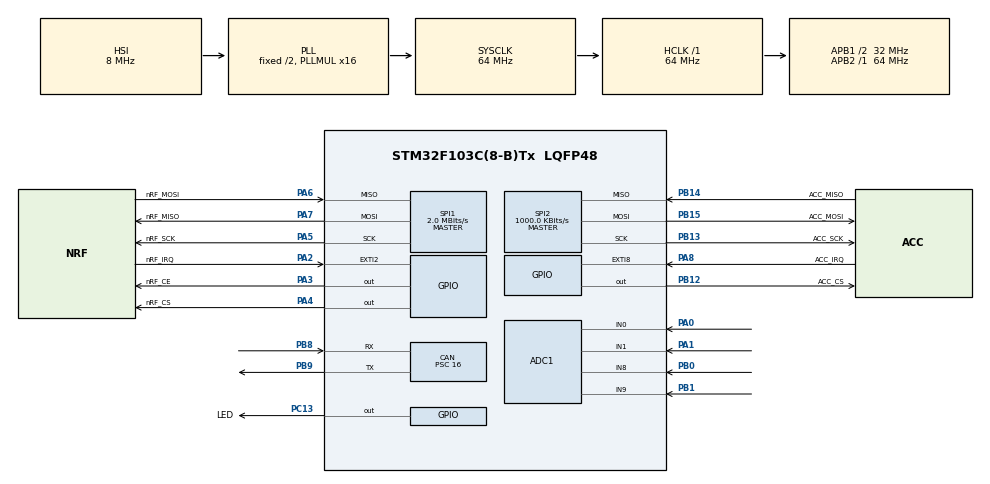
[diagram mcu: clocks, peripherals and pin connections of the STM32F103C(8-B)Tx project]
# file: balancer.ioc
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ADC1.Channel-0\#ChannelRegularConversion=ADC_CHANNEL_0
ADC1.Channel-1\#ChannelRegularConversion=ADC_CHANNEL_1
ADC1.Channel-2\#ChannelRegularConversion=ADC_CHANNEL_8
ADC1.Channel-3\#ChannelRegularConversion=ADC_CHANNEL_9
ADC1.ContinuousConvMode=DISABLE
ADC1.NbrOfConversion=4
ADC1.NbrOfConversionFlag=1
ADC1.Rank-0\#ChannelRegularConversion=1
ADC1.Rank-1\#ChannelRegularConversion=2
ADC1.Rank-2\#ChannelRegularConversion=3
ADC1.Rank-3\#ChannelRegularConversion=4
ADC1.SamplingTime-0\#ChannelRegularConversion=ADC_SAMPLETIME_1CYCLE_5
ADC1.SamplingTime-1\#ChannelRegularConversion=ADC_SAMPLETIME_1CYCLE_5
ADC1.SamplingTime-2\#ChannelRegularConversion=ADC_SAMPLETIME_1CYCLE_5
ADC1.SamplingTime-3\#ChannelRegularConversion=ADC_SAMPLETIME_1CYCLE_5
ADC1.master=1
CAN.BS1=CAN_BS1_2TQ
CAN.CalculateBaudRate=500000
CAN.CalculateTimeBit=2000
CAN.CalculateTimeQuantum=500.0
CAN.Mode=CAN_MODE_NORMAL
CAN.Prescaler=16
FREERTOS.Events01=myEvent01,Static,myEvent01ControlBlock
FREERTOS.Mutexes01=myMutex01,Static,myMutex01ControlBlock,Available
FREERTOS.Tasks01=defaultTask,24,128,StartDefaultTask,Default,NULL,Dynamic,NULL,NULL
FREERTOS.configUSE_NEWLIB_REENTRANT=1
FREERTOS.configUSE_TICKLESS_IDLE=1
Mcu.Family=STM32F1
Mcu.Name=STM32F103C(8-B)Tx
Mcu.Package=LQFP48
NVIC.CAN1_RX1_IRQn=true\:5\:0\:false\:false\:true\:true\:true\:true\:true
NVIC.EXTI2_IRQn=true\:8\:0\:true\:false\:true\:true\:true\:true\:true
NVIC.EXTI9_5_IRQn=true\:5\:0\:false\:false\:true\:true\:true\:true\:true
NVIC.PriorityGroup=NVIC_PRIORITYGROUP_4
NVIC.TIM4_IRQn=true\:15\:0\:false\:false\:true\:false\:false\:true\:true
NVIC.TimeBase=TIM4_IRQn
NVIC.TimeBaseIP=TIM4
NVIC.USB_LP_CAN1_RX0_IRQn=true\:5\:0\:false\:false\:true\:true\:true\:true\:true
PA0-WKUP.Signal=ADCx_IN0
PA1.Signal=ADCx_IN1
PA13.Mode=Serial_Wire
PA13.Signal=SYS_JTMS-SWDIO
PA14.Mode=Serial_Wire
PA14.Signal=SYS_JTCK-SWCLK
PA2.GPIO_Label=nRF_IRQ
PA2.GPIO_ModeDefaultEXTI=GPIO_MODE_IT_FALLING
PA2.GPIO_PuPd=GPIO_PULLUP
PA2.Signal=GPXTI2
PA3.GPIO_Label=nRF_CE
PA3.Signal=GPIO_Output
PA4.GPIO_Label=nRF_CS
PA4.GPIO_Speed=GPIO_SPEED_FREQ_HIGH
PA4.PinState=GPIO_PIN_RESET
PA4.Signal=GPIO_Output
PA5.GPIO_Label=nRF_SCK
PA5.Mode=Full_Duplex_Master
PA5.Signal=SPI1_SCK
PA6.GPIO_Label=nRF_MOSI
PA6.Mode=Full_Duplex_Master
PA6.Signal=SPI1_MISO
PA7.GPIO_Label=nRF_MISO
PA7.Mode=Full_Duplex_Master
PA7.Signal=SPI1_MOSI
PA8.GPIO_Label=ACC_IRQ
PA8.GPIO_PuPd=GPIO_PULLUP
PA8.Signal=GPXTI8
PB0.Signal=ADCx_IN8
PB1.Signal=ADCx_IN9
PB12.GPIO_Label=ACC_CS
PB12.GPIO_Speed=GPIO_SPEED_FREQ_HIGH
PB12.PinState=GPIO_PIN_SET
PB12.Signal=GPIO_Output
PB13.GPIO_Label=ACC_SCK
PB13.Mode=Full_Duplex_Master
PB13.Signal=SPI2_SCK
PB14.GPIO_Label=ACC_MISO
PB14.Mode=Full_Duplex_Master
PB14.Signal=SPI2_MISO
PB15.GPIO_Label=ACC_MOSI
PB15.Mode=Full_Duplex_Master
PB15.Signal=SPI2_MOSI
PB8.Mode=CAN_Activate
PB8.Signal=CAN_RX
PB9.Mode=CAN_Activate
PB9.Signal=CAN_TX
PC13-TAMPER-RTC.GPIO_Label=LED
PC13-TAMPER-RTC.GPIO_Speed=GPIO_SPEED_FREQ_MEDIUM
PC13-TAMPER-RTC.Signal=GPIO_Output
PC14-OSC32_IN.Mode=LSE-External-Oscillator
PC14-OSC32_IN.Signal=RCC_OSC32_IN
PC15-OSC32_OUT.Mode=LSE-External-Oscillator
PC15-OSC32_OUT.Signal=RCC_OSC32_OUT
PD0-OSC_IN.Mode=HSE-External-Oscillator
PD0-OSC_IN.Signal=RCC_OSC_IN
PD1-OSC_OUT.Mode=HSE-External-Oscillator
PD1-OSC_OUT.Signal=RCC_OSC_OUT
ProjectManager.HeapSize=0x200
ProjectManager.StackSize=0x400
ProjectManager.TargetToolchain=STM32CubeIDE
RCC.ADCPresc=RCC_ADCPCLK2_DIV8
RCC.AHBFreq_Value=64000000
RCC.APB1CLKDivider=RCC_HCLK_DIV2
RCC.APB1Freq_Value=32000000
RCC.APB1TimFreq_Value=64000000
RCC.APB2Freq_Value=64000000
RCC.APB2TimFreq_Value=64000000
RCC.HCLKFreq_Value=64000000
RCC.PLLMUL=RCC_PLL_MUL16
RCC.SYSCLKFreq_VALUE=64000000
RCC.SYSCLKSource=RCC_SYSCLKSOURCE_PLLCLK
RCC.USBFreq_Value=64000000
SH.ADCx_IN0.0=ADC1_IN0,IN0
SH.ADCx_IN1.0=ADC1_IN1,IN1
SH.ADCx_IN8.0=ADC1_IN8,IN8
SH.ADCx_IN9.0=ADC1_IN9,IN9
SPI1.BaudRatePrescaler=SPI_BAUDRATEPRESCALER_32
SPI1.CalculateBaudRate=2.0 MBits/s
SPI1.Direction=SPI_DIRECTION_2LINES
SPI1.Mode=SPI_MODE_MASTER
SPI1.VirtualType=VM_MASTER
SPI2.BaudRatePrescaler=SPI_BAUDRATEPRESCALER_32
SPI2.CLKPhase=SPI_PHASE_2EDGE
SPI2.CLKPolarity=SPI_POLARITY_HIGH
SPI2.CalculateBaudRate=1000.0 KBits/s
SPI2.Direction=SPI_DIRECTION_2LINES
SPI2.Mode=SPI_MODE_MASTER
SPI2.VirtualType=VM_MASTER
VP_FREERTOS_VS_CMSIS_V2.Mode=CMSIS_V2
VP_SYS_VS_tim4.Mode=TIM4
board=custom

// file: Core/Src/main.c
/* USER CODE BEGIN Header */
/**
  ******************************************************************************
  * @file           : main.c
  * @brief          : Main program body
  ******************************************************************************
  * @attention
  *
  * Copyright (c) 2026 STMicroelectronics.
  * All rights reserved.
  *
  * This software is licensed under terms that can be found in the LICENSE file
  * in the root directory of this software component.
  * If no LICENSE file comes with this software, it is provided AS-IS.
  *
  ******************************************************************************
  */
/* USER CODE END Header */
#include "main.h"
#include "cmsis_os.h"
#include "adc.h"
#include "can.h"
#include "spi.h"
#include "gpio.h"

/* USER CODE BEGIN Includes */
#include "../common/nrf24.h"
#include "sensor.h"
/* USER CODE END Includes */

void SystemClock_Config(void);
void MX_FREERTOS_Init(void);

int main(void)
{

  /* MCU Configuration--------------------------------------------------------*/

  /* Reset of all peripherals, Initializes the Flash interface and the Systick. */
  HAL_Init();

  /* Configure the system clock */
  SystemClock_Config();

  /* Initialize all configured peripherals */
  MX_GPIO_Init();
  MX_CAN_Init();
  MX_SPI1_Init();
  MX_SPI2_Init();
  MX_ADC1_Init();
  /* USER CODE BEGIN 2 */

  can_start();
  //can_hello_motor(MOTOR0);

  sensor_init();
  sensor_start_continous();

  nrf24_init(nRF24_ROLE_PERIPHERIAL);
  //nrf24_init(nRF24_ROLE_TESTING);
  nrf24_open();
  /* USER CODE END 2 */

  /* Init scheduler */
  osKernelInitialize();  /* Call init function for freertos objects (in cmsis_os2.c) */
  MX_FREERTOS_Init();

  /* Start scheduler */
  osKernelStart();

  /* We should never get here as control is now taken by the scheduler */

  /* Infinite loop */
  while (1)
  {

  }
}

void SystemClock_Config(void)
{
  RCC_OscInitTypeDef RCC_OscInitStruct = {0};
  RCC_ClkInitTypeDef RCC_ClkInitStruct = {0};
  RCC_PeriphCLKInitTypeDef PeriphClkInit = {0};

  /** Initializes the RCC Oscillators according to the specified parameters
  * in the RCC_OscInitTypeDef structure.
  */
  RCC_OscInitStruct.OscillatorType = RCC_OSCILLATORTYPE_HSI;
  RCC_OscInitStruct.HSIState = RCC_HSI_ON;
  RCC_OscInitStruct.HSICalibrationValue = RCC_HSICALIBRATION_DEFAULT;
  RCC_OscInitStruct.PLL.PLLState = RCC_PLL_ON;
  RCC_OscInitStruct.PLL.PLLSource = RCC_PLLSOURCE_HSI_DIV2;
  RCC_OscInitStruct.PLL.PLLMUL = RCC_PLL_MUL16;
  if (HAL_RCC_OscConfig(&RCC_OscInitStruct) != HAL_OK)
  {
    Error_Handler();
  }

  /** Initializes the CPU, AHB and APB buses clocks
  */
  RCC_ClkInitStruct.ClockType = RCC_CLOCKTYPE_HCLK|RCC_CLOCKTYPE_SYSCLK
                              |RCC_CLOCKTYPE_PCLK1|RCC_CLOCKTYPE_PCLK2;
  RCC_ClkInitStruct.SYSCLKSource = RCC_SYSCLKSOURCE_PLLCLK;
  RCC_ClkInitStruct.AHBCLKDivider = RCC_SYSCLK_DIV1;
  RCC_ClkInitStruct.APB1CLKDivider = RCC_HCLK_DIV2;
  RCC_ClkInitStruct.APB2CLKDivider = RCC_HCLK_DIV1;

  if (HAL_RCC_ClockConfig(&RCC_ClkInitStruct, FLASH_LATENCY_2) != HAL_OK)
  {
    Error_Handler();
  }
  PeriphClkInit.PeriphClockSelection = RCC_PERIPHCLK_ADC;
  PeriphClkInit.AdcClockSelection = RCC_ADCPCLK2_DIV8;
  if (HAL_RCCEx_PeriphCLKConfig(&PeriphClkInit) != HAL_OK)
  {
    Error_Handler();
  }
}

void HAL_TIM_PeriodElapsedCallback(TIM_HandleTypeDef *htim)
{
  if (htim->Instance == TIM4)
  {
    HAL_IncTick();
  }
}

void Error_Handler(void)
{
  __disable_irq();
  while (1)
  {
  }
}

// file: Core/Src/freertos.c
/* USER CODE BEGIN Header */
/**
  ******************************************************************************
  * File Name          : freertos.c
  * Description        : Code for freertos applications
  ******************************************************************************
  * @attention
  *
  * Copyright (c) 2026 STMicroelectronics.
  * All rights reserved.
  *
  * This software is licensed under terms that can be found in the LICENSE file
  * in the root directory of this software component.
  * If no LICENSE file comes with this software, it is provided AS-IS.
  *
  ******************************************************************************
  */
/* USER CODE END Header */

#include "FreeRTOS.h"
#include "task.h"
#include "main.h"
#include "cmsis_os.h"

typedef StaticSemaphore_t osStaticMutexDef_t;
typedef StaticEventGroup_t osStaticEventGroupDef_t;

/* Definitions for defaultTask */
osThreadId_t defaultTaskHandle;
const osThreadAttr_t defaultTask_attributes = {
  .name = "defaultTask",
  .stack_size = 128 * 4,
  .priority = (osPriority_t) osPriorityNormal,
};
/* Definitions for myMutex01 */
osMutexId_t myMutex01Handle;
osStaticMutexDef_t myMutex01ControlBlock;
const osMutexAttr_t myMutex01_attributes = {
  .name = "myMutex01",
  .cb_mem = &myMutex01ControlBlock,
  .cb_size = sizeof(myMutex01ControlBlock),
};
/* Definitions for myEvent01 */
osEventFlagsId_t myEvent01Handle;
osStaticEventGroupDef_t myEvent01ControlBlock;
const osEventFlagsAttr_t myEvent01_attributes = {
  .name = "myEvent01",
  .cb_mem = &myEvent01ControlBlock,
  .cb_size = sizeof(myEvent01ControlBlock),
};

void StartDefaultTask(void *argument);

void MX_FREERTOS_Init(void); /* (MISRA C 2004 rule 8.1) */

/* USER CODE BEGIN PREPOSTSLEEP */
__weak void PreSleepProcessing(uint32_t *ulExpectedIdleTime)
{
/* place for user code */
}

__weak void PostSleepProcessing(uint32_t *ulExpectedIdleTime)
{
/* place for user code */
}
/* USER CODE END PREPOSTSLEEP */

void MX_FREERTOS_Init(void) {
  /* Create the mutex(es) */
  /* creation of myMutex01 */
  myMutex01Handle = osMutexNew(&myMutex01_attributes);

  /* Create the thread(s) */
  /* creation of defaultTask */
  defaultTaskHandle = osThreadNew(StartDefaultTask, NULL, &defaultTask_attributes);

  /* creation of myEvent01 */
  myEvent01Handle = osEventFlagsNew(&myEvent01_attributes);

}

void StartDefaultTask(void *argument)
{
  for(;;)
  {
    osDelay(1);
  }
}
